# vpac_targetdb register map
Vendor: Texas Instruments
Registers are 32-bit, read-write, no defined reset value unless marked. A register's access mark holds for its fields unless they carry their own. Offsets are as the file gives them; [hi:lo] are bit positions; {n}, {i} and the like mark numbered series; 'fields as' and 'values as' point back to an identical list.

## VPAC (part 5 of 8) — Vision Pre-Processing Accelerator (VPAC)
{0x1CC+4i} GLBCE_FWD_PERCEPT_LUT_{i:02} access per field (i=0..64) — Forward Perception LUT
  [15:0] VAL rw — LUT Value
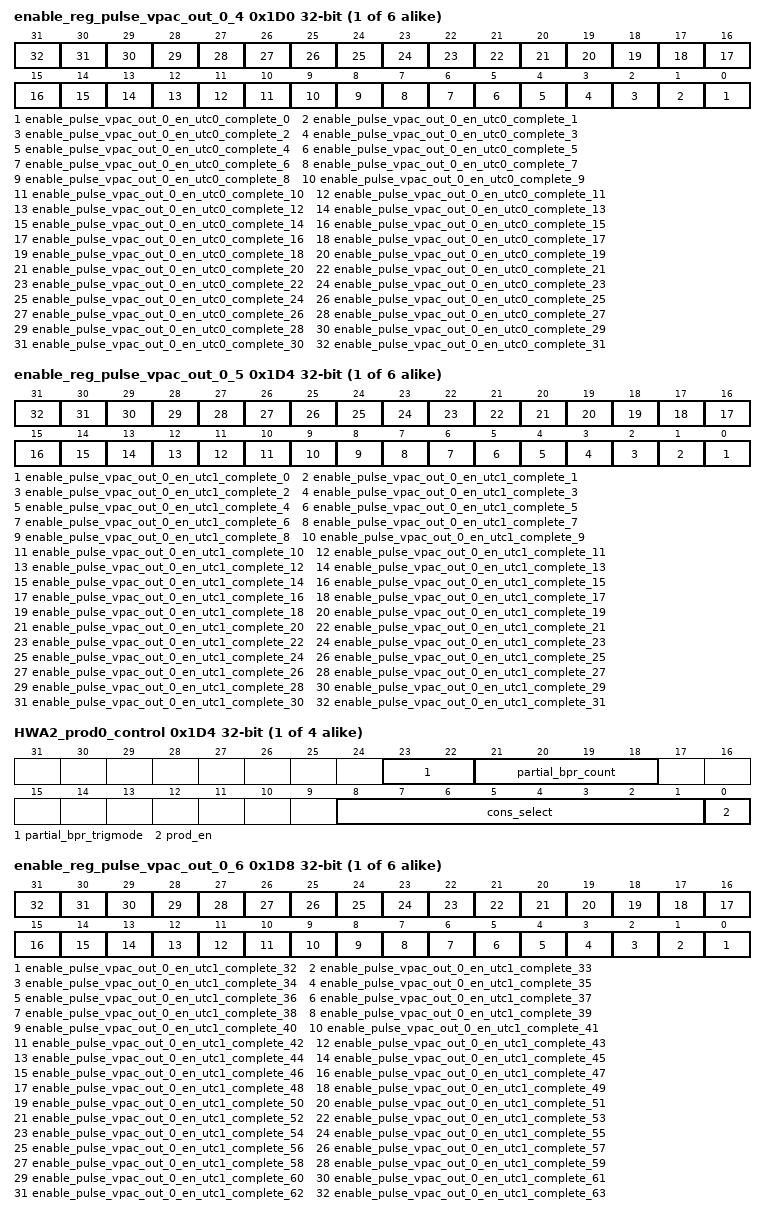
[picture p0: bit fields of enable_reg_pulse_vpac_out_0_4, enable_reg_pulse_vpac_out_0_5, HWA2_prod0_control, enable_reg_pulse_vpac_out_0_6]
{0x1D0+0x20*i} enable_reg_pulse_vpac_out_{i}_4 (i=0..5) — Enable Register {8i+52}
  [n] enable_pulse_vpac_out_{i}_en_utc0_complete_{n} (n=0..31) — Enable Set for pulse_vpac_out_{i}_en_utc0_complete_{n}
{0x1D4+0x20*i} enable_reg_pulse_vpac_out_{i}_5 (i=0..5) — Enable Register {8i+53}
  [n] enable_pulse_vpac_out_{i}_en_utc1_complete_{n} (n=0..31) — Enable Set for pulse_vpac_out_{i}_en_utc1_complete_{n}
{0x1D4+0x14*i} HWA2_prod{i}_control (i=0..3) — Controlling producer socket{i} for HWA2
  [23:22] partial_bpr_trigmode — 0: Normal behavior; 1 : Prod Socket {i} is used to trigger DMA channel to transfer end of Row or End of Region Row buffer data for prod socket ({i}+2)%4. Useful when this Buffer is not completely filled at end of row and it enables triggering separate DMA channel for end of row. Rely on tdone_bpr_early attribute; 2: Prod Socket {i} is used to trigger DMA channel to transfer end of Row or End of Region Row buffer data for prod socket ({i}+2)%4. Useful when this Buffer is not completely filled at end of row and it enables triggering separate DMA channel for end of row. Rely on end of Row attribute. Must not be used in dual output mode
  [21:18] partial_bpr_count — Remaining block count to complete configured BPR at End of Row or End of Region Row when LDC is configured in tdone_gen_mode='0'
  [8:1] cons_select — consumer select for HWA2 prod socket {i}. Used in decrementing count of producer buffer
  [0] prod_en — '1' -> Producer socket 0 enable , '0' Disable
{0x1D8+0x20*i} enable_reg_pulse_vpac_out_{i}_6 (i=0..5) — Enable Register {8i+54}
  [n-32] enable_pulse_vpac_out_{i}_en_utc1_complete_{n} (n=32..63) — Enable Set for pulse_vpac_out_{i}_en_utc1_complete_{n}
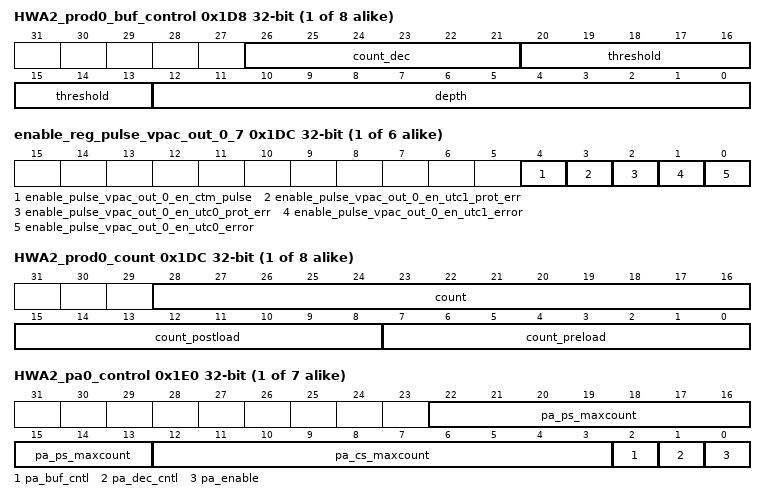
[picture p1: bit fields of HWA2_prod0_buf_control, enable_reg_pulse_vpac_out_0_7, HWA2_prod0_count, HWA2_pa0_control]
{0x1D8+0x14*i} HWA2_prod{i}_buf_control (i=0..7) — Controlling producer socket{i} buffer for HWA2
  [26:21] count_dec — Count decrement value for prod count
  [20:13] threshold — Count threshold to generate pend for consumer
  [12:0] depth — Maximum number of producer buffer count
{0x1DC+0x20*i} enable_reg_pulse_vpac_out_{i}_7 (i=0..5) — Enable Register {8i+55}
  [4] enable_pulse_vpac_out_{i}_en_ctm_pulse — Enable Set for pulse_vpac_out_{i}_en_ctm_pulse
  [3] enable_pulse_vpac_out_{i}_en_utc1_prot_err — Enable Set for pulse_vpac_out_{i}_en_utc1_prot_err
  [2] enable_pulse_vpac_out_{i}_en_utc0_prot_err — Enable Set for pulse_vpac_out_{i}_en_utc0_prot_err
  [1] enable_pulse_vpac_out_{i}_en_utc1_error — Enable Set for pulse_vpac_out_{i}_en_utc1_error
  [0] enable_pulse_vpac_out_{i}_en_utc0_error — Enable Set for pulse_vpac_out_{i}_en_utc0_error
{0x1DC+0x14*i} HWA2_prod{i}_count access per field (i=0..7) — Defining count values for pre/post load for generating pend by HWA2 prod{i}
  [28:16] count ro — current count value
  [15:8] count_postload rw — count postload after producer max thread count reached
  [7:0] count_preload rw — count preload after scheduler start/init
{0x1E0+0x14*i} HWA2_pa{i}_control (i=0..6) — control register to manage pattern adapter on HWA2 prod socket{i}
  [22:13] pa_ps_maxcount — destination count for pattern adaptation (N), M --> N
  [12:3] pa_cs_maxcount — source count for pattern adaptation (M), M --> N
  [2] pa_buf_cntl — '1' -> Apply threshold, count_preload and count_postload on pattern adapter count (use this only when pa_enable='1') '0' -> Apply threshold, count_preload and count_postload on prod count (same behavior as if no pattern adapter. Note when pa_enable='1' and pa_buf_cntl='0' threshold is not used and ignored)
  [1] pa_dec_cntl — '1' -> post pattern adaptation, decrement ps count by count_dec , '0' -> post pattern adaptation, decrement ps count by pa_cs_maxcount
  [0] pa_enable — '1' -> pa enable, '0' -> disable
0x1E0 dbg ro — The DBG register returns the current status of internal FSM - TI internal use only.
  [31:0] status — Debug status
0x1E0 dbg ro — The DBG register returns the current status of internal FSM - TI internal use only.
  [31:0] status — Debug status
0x1E0 dbg ro — The DBG register returns the current status of internal FSM - TI internal use only.
  [31:0] status — Debug status
0x1E0 dbg ro — The DBG register returns the current status of internal FSM - TI internal use only.
  [31:0] status — Debug status
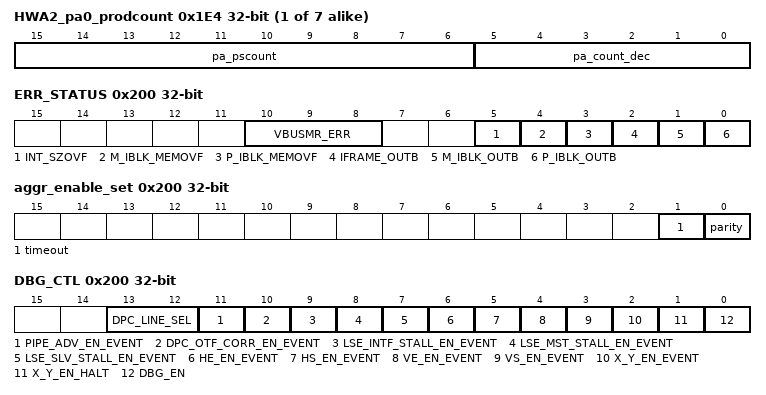
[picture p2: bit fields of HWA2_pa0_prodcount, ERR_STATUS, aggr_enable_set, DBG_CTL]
{0x1E4+0x14*i} HWA2_pa{i}_prodcount access per field (i=0..6) — count values for HWA2 prod socket{i}
  [15:6] pa_pscount ro — current count value of pa prod count
  [5:0] pa_count_dec rw — Decrement count value of pa_prod_count after pattern adapter prod count reaches threshold
0x200 aggr_enable_set — AGGR interrupt enable set Register
  [1] timeout — interrupt enable set for svbus timeout errors
  [0] parity — interrupt enable set for parity errors
0x200 aggr_enable_set — AGGR interrupt enable set Register
  fields as aggr_enable_set
0x200 ERR_STATUS — Control VBUSM Read Interface
  [10:8] VBUSMR_ERR — VBUSM Read I/F Last Error Status. Write '1' to clear, works independently for each bit.
  [5] INT_SZOVF — Internal operation has overflown the HW supported block or frame sizes. Should be fixed
  [4] M_IBLK_MEMOVF — Mesh block storage requirement is more than internal memory available. Should be fixed
  [3] P_IBLK_MEMOVF — Input pixel block storage requirement is more than internal memory available. Should be fixed
  [2] IFRAME_OUTB — Either Mesh data or Input pixel data required is going out of valid frame available
  [1] M_IBLK_OUTB — Mesh Input Block out of Bound. Mesh data required for block is not available in the prefetched internal memory. Should be fine.
  [0] P_IBLK_OUTB — Pixel Input Block out of Bound. Pixel data required for block is not available in the prefetched internal memory. PIX_PAD is not enough
0x200 aggr_enable_set — AGGR interrupt enable set Register
  fields as aggr_enable_set
0x200 DBG_CTL — debug event and control register
  [13:12] DPC_LINE_SEL — select for which dpc line ram to read on debug interface
  [11] PIPE_ADV_EN_EVENT — enable for pixal pipe line advanced
  [10] DPC_OTF_CORR_EN_EVENT — enable for dpc otf corrected a pixel
  [9] LSE_INTF_STALL_EN_EVENT — enable for lse slave port stalled by rawfe
  [8] LSE_MST_STALL_EN_EVENT — enable for lse maaster port stalled on H3A out I/F
  [7] LSE_SLV_STALL_EN_EVENT — enable for lse not sending data in frame on pixel I/F
  [6] HE_EN_EVENT — enable for horizantal end
  [5] HS_EN_EVENT — enable for horizantal start
  [4] VE_EN_EVENT — enable for verticle end
  [3] VS_EN_EVENT — enable for verticle start
  [2] X_Y_EN_EVENT — enable for x,y position match event; Only generates event, no halt
  [1] X_Y_EN_HALT — enable for x,y position match halt; Halts Pipe, clear this bit to resume. Only way to resume is to clear this bit back to 0. You would need to clear the status bit after clearing this bit.
  [0] DBG_EN — Enable debug features, set to '0' to disable all events
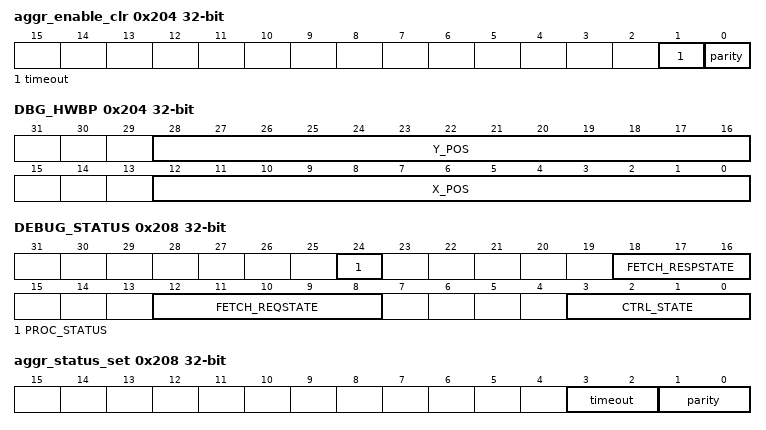
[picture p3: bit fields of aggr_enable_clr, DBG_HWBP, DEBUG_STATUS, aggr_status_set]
0x204 aggr_enable_clr — AGGR interrupt enable clear Register
  [1] timeout — interrupt enable clear for svbus timeout errors
  [0] parity — interrupt enable clear for parity errors
0x204 aggr_enable_clr — AGGR interrupt enable clear Register
  fields as aggr_enable_clr
0x204 DEBUG_CTRL — Control the memory access selection
  [0] CFG_MEMACC_SEL — VBUSP Configuration access control. 0 - VBUSP can access Ping memories 1 - VBUSP can access pong memories All private memories Mesh,Luma, Chroma will share same control. Ping and pong memories will have same memory map
0x204 aggr_enable_clr — AGGR interrupt enable clear Register
  fields as aggr_enable_clr
0x204 DBG_HWBP — x,y event for event matching
  [28:16] Y_POS — pixel y position
  [12:0] X_POS — pixel x position
0x208 aggr_status_set — AGGR interrupt status set Register
  [3:2] timeout — interrupt status set for svbus timeout errors
  [1:0] parity — interrupt status set for parity errors
0x208 aggr_status_set — AGGR interrupt status set Register
  fields as aggr_status_set
0x208 DEBUG_STATUS ro — LDC Debug Status Register
  [24] PROC_STATUS — Block Processing status. 0 - Block Processing is ongoing 1 - Either block processing is completed or not started
  [18:16] FETCH_RESPSTATE — VBUSM Fetch Response state machine 3'd0 = ST_RESP_IDLE 3'd1 = ST_RESP_MREQWAIT 3'd2 = ST_RESP_MRESPWAIT 3'd3 = ST_RESP_IREQWAIT 3'd4 = ST_RESP_IRESPWAIT 3'd5 = ST_RESP_DONE
  [12:8] FETCH_REQSTATE — VBUSM Fetch Request state machine 5'b00_000 = ST_REQ_IDLE 5'b10_000 = ST_REQ_MBASECAL 5'b10_001 = ST_REQ_MDATA 5'b11_000 = ST_REQ_INITWAIT 5'b11_001 = ST_REQ_ICBUF 5'b11_010 = ST_REQ_IBASECAL 5'b11_011 = ST_REQ_IDATA
  [3:0] CTRL_STATE — Main Control State machine 4'd0 = STATE_IDLE 4'd1 = STATE_GET_BLOCK_P1 4'd2 = STATE_GET_BLOCK_P2 4'd3 = STATE_GET_BLOCK_P3 4'd4 = STATE_GET_BLOCK_P4 4'd5 = STATE_SET_BLOCK_PWARP 4'd6 = STATE_SET_BLOCK_MESHDC 4'd7 = STATE_INIT_BLOCK 4'd8 = STATE_GET_BLOCK 4'd9 = STATE_WAIT_PROCESS_DONE 4'd10 = STATE_LAST_PROCESS 4'd11 = STATE_LAST_PROCESS_DONE
0x208 aggr_status_set — AGGR interrupt status set Register
  fields as aggr_status_set
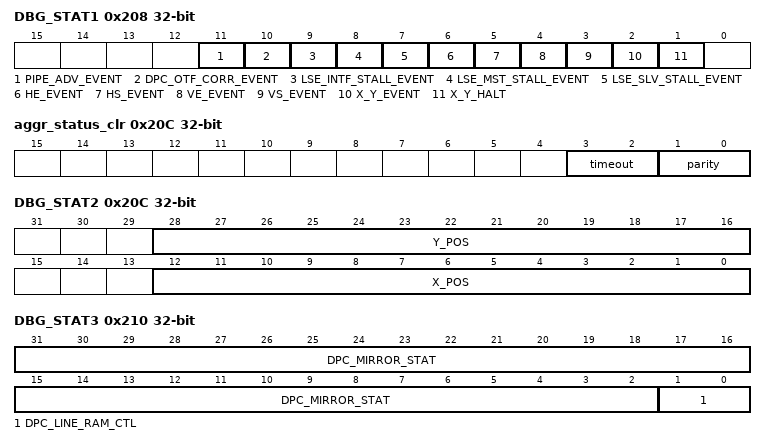
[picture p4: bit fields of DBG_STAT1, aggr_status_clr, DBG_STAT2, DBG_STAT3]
0x208 DBG_STAT1 — status/clear register for debug events
  [11] PIPE_ADV_EVENT — status/clear for pixal pipe line advanced
  [10] DPC_OTF_CORR_EVENT — status/clear for dpc otf corrected a pixel. write 1 to clear event status, write of 0 has no affect
  [9] LSE_INTF_STALL_EVENT — status/clear for lse slave port stalled by rawfe. write 1 to clear event status, write of 0 has no affect
  [8] LSE_MST_STALL_EVENT — status/clear for lse maaster port stalled. write 1 to clear event status, write of 0 has no affect
  [7] LSE_SLV_STALL_EVENT — status/clear for lse not sending data in frame. write 1 to clear event status, write of 0 has no affect
  [6] HE_EVENT — status/clear for horizantal end. write 1 to clear event status, write of 0 has no affect
  [5] HS_EVENT — status/clear for horizantal start. write 1 to clear event status, write of 0 has no affect
  [4] VE_EVENT — status/clear for verticle end. write 1 to clear event status, write of 0 has no affect
  [3] VS_EVENT — status/clear for verticle start. write 1 to clear event status, write of 0 has no affect
  [2] X_Y_EVENT — status/clear for x,y position match event. write 1 to clear event status, write of 0 has no affect
  [1] X_Y_HALT — status/clear for x,y position match halt. write 1 to clear event status, write of 0 has no affect
0x20C aggr_status_clr — AGGR interrupt status clear Register
  [3:2] timeout — interrupt status clear for svbus timeout errors
  [1:0] parity — interrupt status clear for parity errors
0x20C aggr_status_clr — AGGR interrupt status clear Register
  fields as aggr_status_clr
0x20C FR_PDFTCH ro — Pixel bytes fetched by VBUSM Read Interface. It is updated on every command issued and cleared at the beginning frame fetch. Reading at the end of the frame will provide total number of pixel data fetched for entire frame
  [31:0] PBYTES — Pixel bytes fetched for current Frame. Reading at the end of frame will provide pixel data fetched for entire frame
0x20C aggr_status_clr — AGGR interrupt status clear Register
  fields as aggr_status_clr
0x20C DBG_STAT2 ro — current x,y position in frame
  [28:16] Y_POS — current y position
  [12:0] X_POS — current x position
0x210 FR_MDFTCH ro — Mesh bytes fetched by VBUSM Read Interface. It is updated on every command issued and cleared at the beginning frame fetch. Reading at the end of the frame will provide total number of mesh data band fetched for entire frame
  [31:0] MBYTES — Mesh bytes fetched for current Frame. Reading at the end of frame will provide Mesh data fetched for entire frame
0x210 DBG_STAT3 ro — internal state status
  [31:2] DPC_MIRROR_STAT — dpc mirror status
  [1:0] DPC_LINE_RAM_CTL — ram control for understanding the phase of DPC line rams circular buffer for debug reads
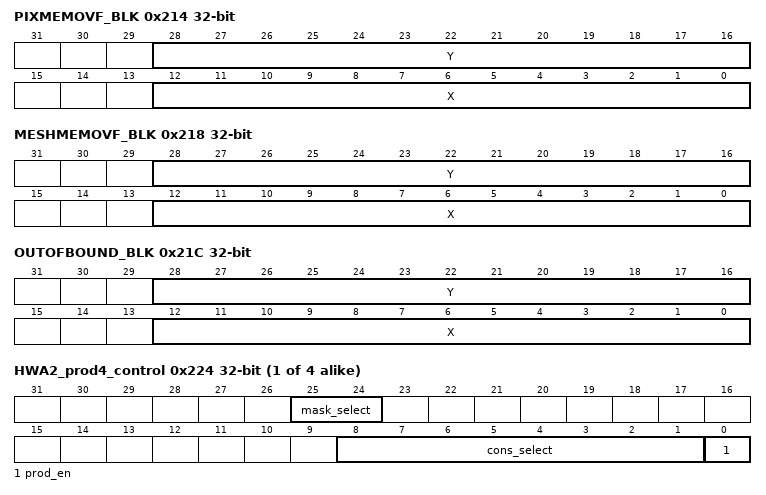
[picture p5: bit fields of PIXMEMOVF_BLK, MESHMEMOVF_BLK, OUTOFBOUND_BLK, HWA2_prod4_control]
0x214 PIXMEMOVF_BLK ro — Starting co-ordinates of first output block for which input pixel buffer overflowed
  [28:16] Y — Start Y Co-ordinate
  [12:0] X — Start X Co-ordinate
0x214 DBG_STAT4 ro — internal state status
  [31:0] LSC_DBG_STAT — lsc state machine
0x218 MESHMEMOVF_BLK ro — Starting co-ordinates of first output block for which input mesh buffer overflowed
  [28:16] Y — Start Y Co-ordinate
  [12:0] X — Start X Co-ordinate
0x21C OUTOFBOUND_BLK ro — Starting co-ordinates of first output block for which PIX_PAD is not enough
  [28:16] Y — Start Y Co-ordinate
  [12:0] X — Start X Co-ordinate
{0x1D4+0x14*i} HWA2_prod{i}_control (i=4..7) — Controlling producer socket{i} for HWA2
  [25:24] mask_select — define which tdone_mask apply to prod socket {i}. tdone_mask[mask_select] applies to prod_socket{i}.
  [8:1] cons_select — consumer select for HWA2 prod socket {i}. Used in decrementing count of producer buffer
  [0] prod_en — '1' -> Producer socket 0 enable , '0' Disable
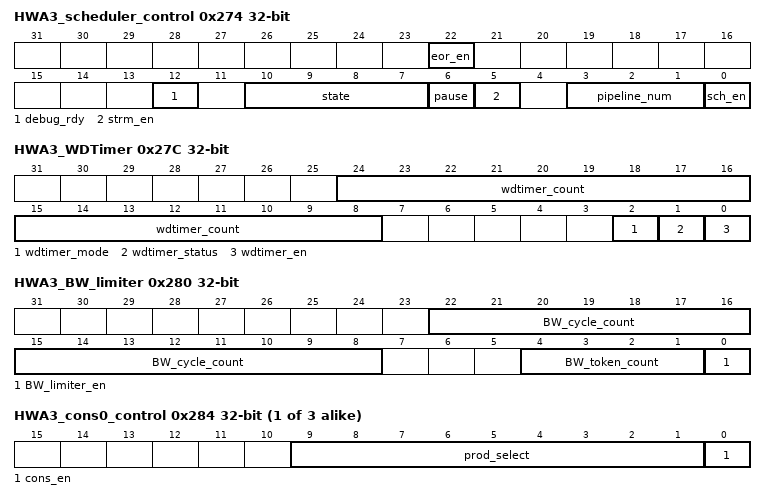
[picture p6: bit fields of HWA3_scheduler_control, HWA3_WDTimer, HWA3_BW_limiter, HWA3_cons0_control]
0x274 HWA3_scheduler_control access per field — Scheduler Control Register
  [22] eor_en rw — '1' -> LDC REGION/sub-frame feature enabled, '0' LDC works in Frame mode only
  [12] debug_rdy rw — '0' -> HWA3 Scheduler resources must not be read during halted state. '1'-> HWA3 Scheduler resources are readable during halted state
  [10:7] state ro — Current state of HWA3 Scheduler
  [6] pause rw — '1' -> pause/suspend scheduler , '0' -> resume scheduler
  [5] strm_en rw — '1' -> Streaming input enable, '0' No streaming input
  [3:1] pipeline_num rw — Pipeline Number of HWA3 Scheduler
  [0] sch_en rw — scheduler enable; write '1' to enable scheduler
0x27C HWA3_WDTimer access per field — Watchdog timer control register
  [24:8] wdtimer_count ro — Current value of HWA3 Scheduler watchdog timer count
  [2] wdtimer_mode rw — Watchdog timeout count '1' -> 128K , '0' -> 64K
  [1] wdtimer_status ro — HWA3 Scheduler watchdog timer status '1' -> Timer Active '0' -> Timer Inactive (count is stable)
  [0] wdtimer_en rw — '1' -> activate watchdog timer for 64K VPAC/DMPAC cycles between task start and task done '0' -> Disable watchdog timer
0x280 HWA3_BW_limiter — Scheduler BW Control Register. Processing unit level BW control. Use DMA to eliminate peak system BW within processing units line/Block
  [22:8] BW_cycle_count — Average Cycle count between successive Task Start
  [4:1] BW_token_count — Max Token count to create average BW
  [0] BW_limiter_en — '1' -> Enable BW limiter function for HWA3 sch, '0' --> Disable
{0x284+4i} HWA3_cons{i}_control (i=0..2) — Controlling consumer socket {i} for HWA3
  [9:1] prod_select — producer select for HWA3 cons socket {i}
  [0] cons_en — '1' -> Consumer socket {i} enable , '0' Disable
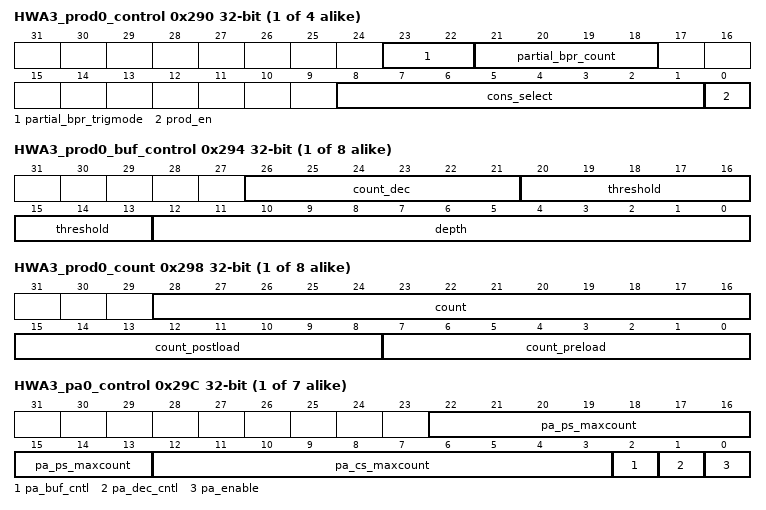
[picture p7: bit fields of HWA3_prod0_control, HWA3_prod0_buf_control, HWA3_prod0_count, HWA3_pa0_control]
{0x290+0x14*i} HWA3_prod{i}_control (i=0..3) — Controlling producer socket{i} for HWA3
  [23:22] partial_bpr_trigmode — 0: Normal behavior; 1 : Prod Socket {i} is used to trigger DMA channel to transfer end of Row or End of Region Row buffer data for prod socket ({i}+2)%4. Useful when this Buffer is not completely filled at end of row and it enables triggering separate DMA channel for end of row. Rely on tdone_bpr_early attribute; 2: Prod Socket {i} is used to trigger DMA channel to transfer end of Row or End of Region Row buffer data for prod socket ({i}+2)%4. Useful when this Buffer is not completely filled at end of row and it enables triggering separate DMA channel for end of row. Rely on end of Row attribute. Must not be used in dual output mode
  [21:18] partial_bpr_count — Remaining block count to complete configured BPR at End of Row or End of Region Row when LDC is configured in tdone_gen_mode='0'
  [8:1] cons_select — consumer select for HWA3 prod socket {i}. Used in decrementing count of producer buffer
  [0] prod_en — '1' -> Producer socket 0 enable , '0' Disable
{0x294+0x14*i} HWA3_prod{i}_buf_control (i=0..7) — Controlling producer socket{i} buffer for HWA3
  fields as HWA2_prod0_buf_control
{0x298+0x14*i} HWA3_prod{i}_count access per field (i=0..7) — Defining count values for pre/post load for generating pend by HWA3 prod{i}
  fields as HWA2_prod0_count
{0x29C+0x14*i} HWA3_pa{i}_control (i=0..6) — control register to manage pattern adapter on HWA3 prod socket{i}
  fields as HWA2_pa0_control
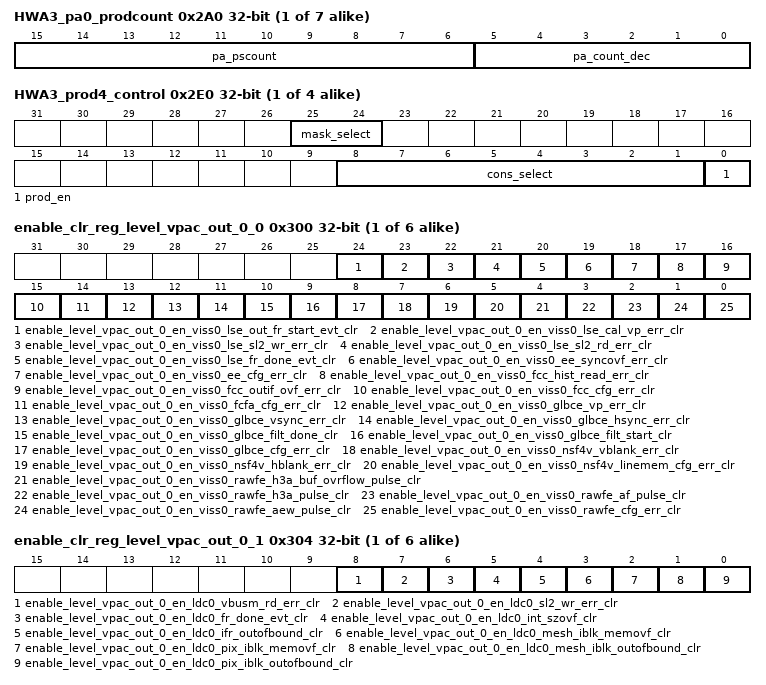
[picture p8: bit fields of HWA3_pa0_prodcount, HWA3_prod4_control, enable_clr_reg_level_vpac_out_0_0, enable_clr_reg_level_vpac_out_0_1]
{0x2A0+0x14*i} HWA3_pa{i}_prodcount access per field (i=0..6) — count values for HWA3 prod socket{i}
  fields as HWA2_pa0_prodcount
0x2D0 GLBCE_WDR_GAMMA_EN access per field — WDR Gamma LUT Enable
  [0] EN rw — Frontend WDR LUT enable
{0x2D4+4i} GLBCE_WDR_GAMMA_LUT_{i:02} access per field (i=0..99) — Frontend WDR LUT
  [15:0] VAL rw — LUT Value
{0x290+0x14*i} HWA3_prod{i}_control (i=4..7) — Controlling producer socket{i} for HWA3
  [25:24] mask_select — define which tdone_mask apply to prod socket {i}. tdone_mask[mask_select] applies to prod_socket{i}.
  [8:1] cons_select — consumer select for HWA3 prod socket {i}. Used in decrementing count of producer buffer
  [0] prod_en — '1' -> Producer socket 0 enable , '0' Disable
{0x300+0x20*i} enable_clr_reg_level_vpac_out_{i}_0 (i=0..5) — Enable Clear Register {8i}
  [24] enable_level_vpac_out_{i}_en_viss0_lse_out_fr_start_evt_clr — Enable Clear for level_vpac_out_{i}_en_viss0_lse_out_fr_start_evt
  [23] enable_level_vpac_out_{i}_en_viss0_lse_cal_vp_err_clr — Enable Clear for level_vpac_out_{i}_en_viss0_lse_cal_vp_err
  [22] enable_level_vpac_out_{i}_en_viss0_lse_sl2_wr_err_clr — Enable Clear for level_vpac_out_{i}_en_viss0_lse_sl2_wr_err
  [21] enable_level_vpac_out_{i}_en_viss0_lse_sl2_rd_err_clr — Enable Clear for level_vpac_out_{i}_en_viss0_lse_sl2_rd_err
  [20] enable_level_vpac_out_{i}_en_viss0_lse_fr_done_evt_clr — Enable Clear for level_vpac_out_{i}_en_viss0_lse_fr_done_evt
  [19] enable_level_vpac_out_{i}_en_viss0_ee_syncovf_err_clr — Enable Clear for level_vpac_out_{i}_en_viss0_ee_syncovf_err
  [18] enable_level_vpac_out_{i}_en_viss0_ee_cfg_err_clr — Enable Clear for level_vpac_out_{i}_en_viss0_ee_cfg_err
  [17] enable_level_vpac_out_{i}_en_viss0_fcc_hist_read_err_clr — Enable Clear for level_vpac_out_{i}_en_viss0_fcc_hist_read_err
  [16] enable_level_vpac_out_{i}_en_viss0_fcc_outif_ovf_err_clr — Enable Clear for level_vpac_out_{i}_en_viss0_fcc_outif_ovf_err
  [15] enable_level_vpac_out_{i}_en_viss0_fcc_cfg_err_clr — Enable Clear for level_vpac_out_{i}_en_viss0_fcc_cfg_err
  [14] enable_level_vpac_out_{i}_en_viss0_fcfa_cfg_err_clr — Enable Clear for level_vpac_out_{i}_en_viss0_fcfa_cfg_err
  [13] enable_level_vpac_out_{i}_en_viss0_glbce_vp_err_clr — Enable Clear for level_vpac_out_{i}_en_viss0_glbce_vp_err
  [12] enable_level_vpac_out_{i}_en_viss0_glbce_vsync_err_clr — Enable Clear for level_vpac_out_{i}_en_viss0_glbce_vsync_err
  [11] enable_level_vpac_out_{i}_en_viss0_glbce_hsync_err_clr — Enable Clear for level_vpac_out_{i}_en_viss0_glbce_hsync_err
  [10] enable_level_vpac_out_{i}_en_viss0_glbce_filt_done_clr — Enable Clear for level_vpac_out_{i}_en_viss0_glbce_filt_done
  [9] enable_level_vpac_out_{i}_en_viss0_glbce_filt_start_clr — Enable Clear for level_vpac_out_{i}_en_viss0_glbce_filt_start
  [8] enable_level_vpac_out_{i}_en_viss0_glbce_cfg_err_clr — Enable Clear for level_vpac_out_{i}_en_viss0_glbce_cfg_err
  [7] enable_level_vpac_out_{i}_en_viss0_nsf4v_vblank_err_clr — Enable Clear for level_vpac_out_{i}_en_viss0_nsf4v_vblank_err
  [6] enable_level_vpac_out_{i}_en_viss0_nsf4v_hblank_err_clr — Enable Clear for level_vpac_out_{i}_en_viss0_nsf4v_hblank_err
  [5] enable_level_vpac_out_{i}_en_viss0_nsf4v_linemem_cfg_err_clr — Enable Clear for level_vpac_out_{i}_en_viss0_nsf4v_linemem_cfg_err
  [4] enable_level_vpac_out_{i}_en_viss0_rawfe_h3a_buf_ovrflow_pulse_clr — Enable Clear for level_vpac_out_{i}_en_viss0_rawfe_h3a_buf_ovrflow_pulse
  [3] enable_level_vpac_out_{i}_en_viss0_rawfe_h3a_pulse_clr — Enable Clear for level_vpac_out_{i}_en_viss0_rawfe_h3a_pulse
  [2] enable_level_vpac_out_{i}_en_viss0_rawfe_af_pulse_clr — Enable Clear for level_vpac_out_{i}_en_viss0_rawfe_af_pulse
  [1] enable_level_vpac_out_{i}_en_viss0_rawfe_aew_pulse_clr — Enable Clear for level_vpac_out_{i}_en_viss0_rawfe_aew_pulse
  [0] enable_level_vpac_out_{i}_en_viss0_rawfe_cfg_err_clr — Enable Clear for level_vpac_out_{i}_en_viss0_rawfe_cfg_err
{0x304+0x20*i} enable_clr_reg_level_vpac_out_{i}_1 (i=0..5) — Enable Clear Register {8i+1}
  [8] enable_level_vpac_out_{i}_en_ldc0_vbusm_rd_err_clr — Enable Clear for level_vpac_out_{i}_en_ldc0_vbusm_rd_err
  [7] enable_level_vpac_out_{i}_en_ldc0_sl2_wr_err_clr — Enable Clear for level_vpac_out_{i}_en_ldc0_sl2_wr_err
  [6] enable_level_vpac_out_{i}_en_ldc0_fr_done_evt_clr — Enable Clear for level_vpac_out_{i}_en_ldc0_fr_done_evt
  [5] enable_level_vpac_out_{i}_en_ldc0_int_szovf_clr — Enable Clear for level_vpac_out_{i}_en_ldc0_int_szovf
  [4] enable_level_vpac_out_{i}_en_ldc0_ifr_outofbound_clr — Enable Clear for level_vpac_out_{i}_en_ldc0_ifr_outofbound
  [3] enable_level_vpac_out_{i}_en_ldc0_mesh_iblk_memovf_clr — Enable Clear for level_vpac_out_{i}_en_ldc0_mesh_iblk_memovf
  [2] enable_level_vpac_out_{i}_en_ldc0_pix_iblk_memovf_clr — Enable Clear for level_vpac_out_{i}_en_ldc0_pix_iblk_memovf
  [1] enable_level_vpac_out_{i}_en_ldc0_mesh_iblk_outofbound_clr — Enable Clear for level_vpac_out_{i}_en_ldc0_mesh_iblk_outofbound
  [0] enable_level_vpac_out_{i}_en_ldc0_pix_iblk_outofbound_clr — Enable Clear for level_vpac_out_{i}_en_ldc0_pix_iblk_outofbound
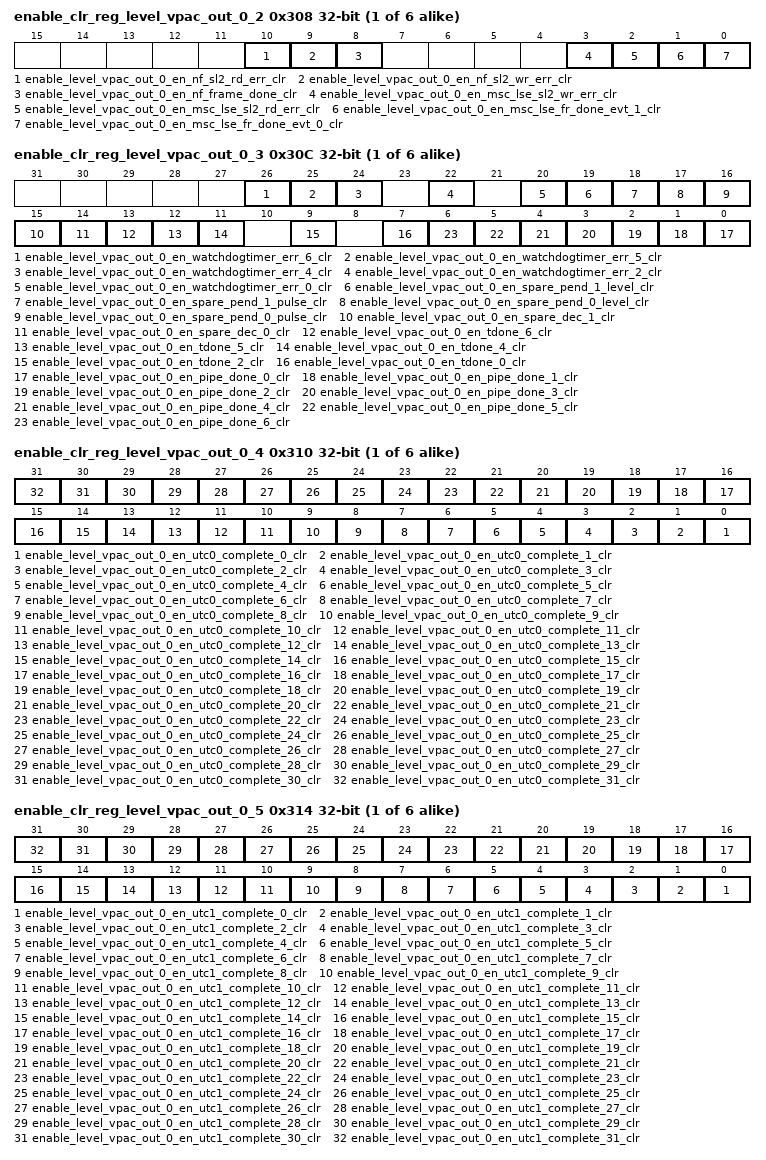
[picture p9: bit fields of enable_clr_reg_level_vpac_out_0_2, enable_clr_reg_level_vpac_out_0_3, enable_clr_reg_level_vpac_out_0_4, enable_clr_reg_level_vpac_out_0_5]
{0x308+0x20*i} enable_clr_reg_level_vpac_out_{i}_2 (i=0..5) — Enable Clear Register {8i+2}
  [10] enable_level_vpac_out_{i}_en_nf_sl2_rd_err_clr — Enable Clear for level_vpac_out_{i}_en_nf_sl2_rd_err
  [9] enable_level_vpac_out_{i}_en_nf_sl2_wr_err_clr — Enable Clear for level_vpac_out_{i}_en_nf_sl2_wr_err
  [8] enable_level_vpac_out_{i}_en_nf_frame_done_clr — Enable Clear for level_vpac_out_{i}_en_nf_frame_done
  [3] enable_level_vpac_out_{i}_en_msc_lse_sl2_wr_err_clr — Enable Clear for level_vpac_out_{i}_en_msc_lse_sl2_wr_err
  [2] enable_level_vpac_out_{i}_en_msc_lse_sl2_rd_err_clr — Enable Clear for level_vpac_out_{i}_en_msc_lse_sl2_rd_err
  [1] enable_level_vpac_out_{i}_en_msc_lse_fr_done_evt_1_clr — Enable Clear for level_vpac_out_{i}_en_msc_lse_fr_done_evt_1
  [0] enable_level_vpac_out_{i}_en_msc_lse_fr_done_evt_0_clr — Enable Clear for level_vpac_out_{i}_en_msc_lse_fr_done_evt_0
{0x30C+0x20*i} enable_clr_reg_level_vpac_out_{i}_3 (i=0..5) — Enable Clear Register {8i+3}
  [26] enable_level_vpac_out_{i}_en_watchdogtimer_err_6_clr — Enable Clear for level_vpac_out_{i}_en_watchdogtimer_err_6
  [25] enable_level_vpac_out_{i}_en_watchdogtimer_err_5_clr — Enable Clear for level_vpac_out_{i}_en_watchdogtimer_err_5
  [24] enable_level_vpac_out_{i}_en_watchdogtimer_err_4_clr — Enable Clear for level_vpac_out_{i}_en_watchdogtimer_err_4
  [22] enable_level_vpac_out_{i}_en_watchdogtimer_err_2_clr — Enable Clear for level_vpac_out_{i}_en_watchdogtimer_err_2
  [20] enable_level_vpac_out_{i}_en_watchdogtimer_err_0_clr — Enable Clear for level_vpac_out_{i}_en_watchdogtimer_err_0
  [19] enable_level_vpac_out_{i}_en_spare_pend_1_level_clr — Enable Clear for level_vpac_out_{i}_en_spare_pend_1_level
  [18] enable_level_vpac_out_{i}_en_spare_pend_1_pulse_clr — Enable Clear for level_vpac_out_{i}_en_spare_pend_1_pulse
  [17] enable_level_vpac_out_{i}_en_spare_pend_0_level_clr — Enable Clear for level_vpac_out_{i}_en_spare_pend_0_level
  [16] enable_level_vpac_out_{i}_en_spare_pend_0_pulse_clr — Enable Clear for level_vpac_out_{i}_en_spare_pend_0_pulse
  [15] enable_level_vpac_out_{i}_en_spare_dec_1_clr — Enable Clear for level_vpac_out_{i}_en_spare_dec_1
  [14] enable_level_vpac_out_{i}_en_spare_dec_0_clr — Enable Clear for level_vpac_out_{i}_en_spare_dec_0
  [13] enable_level_vpac_out_{i}_en_tdone_6_clr — Enable Clear for level_vpac_out_{i}_en_tdone_6
  [12] enable_level_vpac_out_{i}_en_tdone_5_clr — Enable Clear for level_vpac_out_{i}_en_tdone_5
  [11] enable_level_vpac_out_{i}_en_tdone_4_clr — Enable Clear for level_vpac_out_{i}_en_tdone_4
  [9] enable_level_vpac_out_{i}_en_tdone_2_clr — Enable Clear for level_vpac_out_{i}_en_tdone_2
  [7] enable_level_vpac_out_{i}_en_tdone_0_clr — Enable Clear for level_vpac_out_{i}_en_tdone_0
  [n] enable_level_vpac_out_{i}_en_pipe_done_{n}_clr (n=0..6) — Enable Clear for level_vpac_out_{i}_en_pipe_done_{n}
{0x310+0x20*i} enable_clr_reg_level_vpac_out_{i}_4 (i=0..5) — Enable Clear Register {8i+4}
  [n] enable_level_vpac_out_{i}_en_utc0_complete_{n}_clr (n=0..31) — Enable Clear for level_vpac_out_{i}_en_utc0_complete_{n}
{0x314+0x20*i} enable_clr_reg_level_vpac_out_{i}_5 (i=0..5) — Enable Clear Register {8i+5}
  [n] enable_level_vpac_out_{i}_en_utc1_complete_{n}_clr (n=0..31) — Enable Clear for level_vpac_out_{i}_en_utc1_complete_{n}
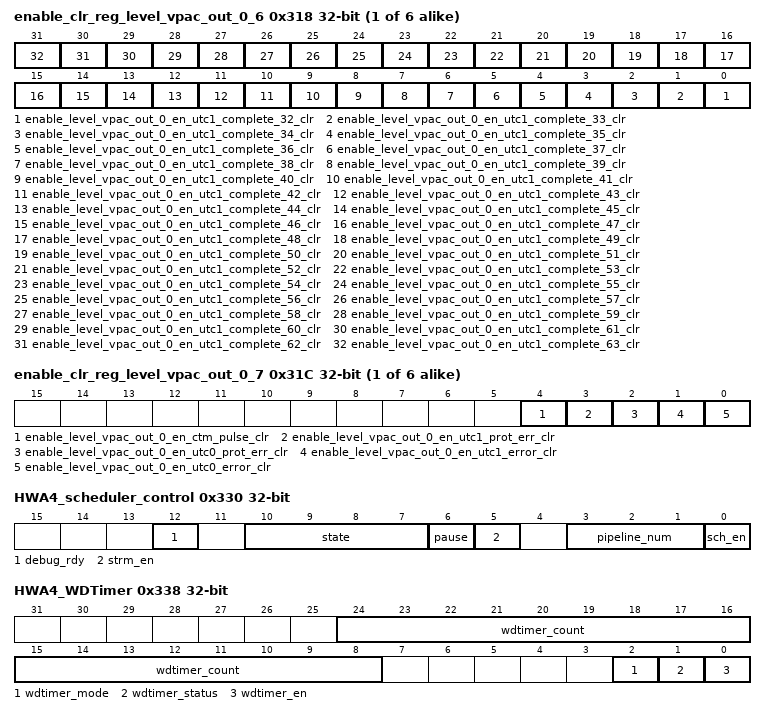
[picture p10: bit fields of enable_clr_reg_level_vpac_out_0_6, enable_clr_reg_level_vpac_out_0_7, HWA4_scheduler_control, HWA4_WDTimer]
{0x318+0x20*i} enable_clr_reg_level_vpac_out_{i}_6 (i=0..5) — Enable Clear Register {8i+6}
  [n-32] enable_level_vpac_out_{i}_en_utc1_complete_{n}_clr (n=32..63) — Enable Clear for level_vpac_out_{i}_en_utc1_complete_{n}
{0x31C+0x20*i} enable_clr_reg_level_vpac_out_{i}_7 (i=0..5) — Enable Clear Register {8i+7}
  [4] enable_level_vpac_out_{i}_en_ctm_pulse_clr — Enable Clear for level_vpac_out_{i}_en_ctm_pulse
  [3] enable_level_vpac_out_{i}_en_utc1_prot_err_clr — Enable Clear for level_vpac_out_{i}_en_utc1_prot_err
  [2] enable_level_vpac_out_{i}_en_utc0_prot_err_clr — Enable Clear for level_vpac_out_{i}_en_utc0_prot_err
  [1] enable_level_vpac_out_{i}_en_utc1_error_clr — Enable Clear for level_vpac_out_{i}_en_utc1_error
  [0] enable_level_vpac_out_{i}_en_utc0_error_clr — Enable Clear for level_vpac_out_{i}_en_utc0_error
0x330 HWA4_scheduler_control access per field — Scheduler Control Register
  [12] debug_rdy rw — '0' -> HWA4 Scheduler resources must not be read during halted state. '1'-> HWA4 Scheduler resources are readable during halted state
  [10:7] state ro — Current state of HWA4 Scheduler
  [6] pause rw — '1' -> pause/suspend scheduler , '0' -> resume scheduler
  [5] strm_en rw — '1' -> Streaming input enable, '0' No streaming input
  [3:1] pipeline_num rw — Pipeline Number of HWA4 Scheduler
  [0] sch_en rw — scheduler enable; write '1' to enable scheduler
0x338 HWA4_WDTimer access per field — Watchdog timer control register
  [24:8] wdtimer_count ro — Current value of HWA4 Scheduler watchdog timer count
  [2] wdtimer_mode rw — Watchdog timeout count '1' -> 128K , '0' -> 64K
  [1] wdtimer_status ro — HWA4 Scheduler watchdog timer status '1' -> Timer Active '0' -> Timer Inactive (count is stable)
  [0] wdtimer_en rw — '1' -> activate watchdog timer for 64K VPAC/DMPAC cycles between task start and task done '0' -> Disable watchdog timer
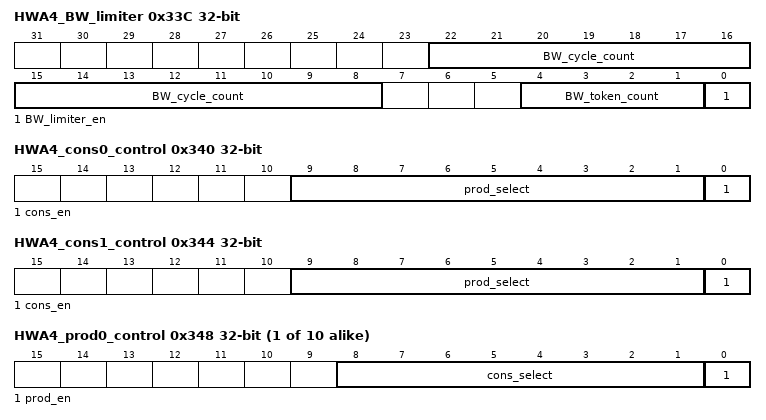
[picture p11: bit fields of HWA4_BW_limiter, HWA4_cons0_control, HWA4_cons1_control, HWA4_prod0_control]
0x33C HWA4_BW_limiter — Scheduler BW Control Register. Processing unit level BW control. Use DMA to eliminate peak system BW within processing units line/Block
  [22:8] BW_cycle_count — Average Cycle count between successive Task Start
  [4:1] BW_token_count — Max Token count to create average BW
  [0] BW_limiter_en — '1' -> Enable BW limiter function for HWA4 sch, '0' --> Disable
0x340 HWA4_cons0_control — Controlling consumer socket 0 for HWA4
  [9:1] prod_select — producer select for HWA4 cons socket 0
  [0] cons_en — '1' -> Consumer socket 0 enable , '0' Disable
0x344 HWA4_cons1_control — Controlling consumer socket 1 for HWA4
  [9:1] prod_select — producer select for HWA4 cons socket 1
  [0] cons_en — '1' -> Consumer socket 1 enable , '0' Disable
{0x348+0x14*i} HWA4_prod{i}_control (i=0..9) — Controlling producer socket{i} for HWA4
  [8:1] cons_select — consumer select for HWA4 prod socket {i}. Used in decrementing count of producer buffer
  [0] prod_en — '1' -> Producer socket 0 enable , '0' Disable
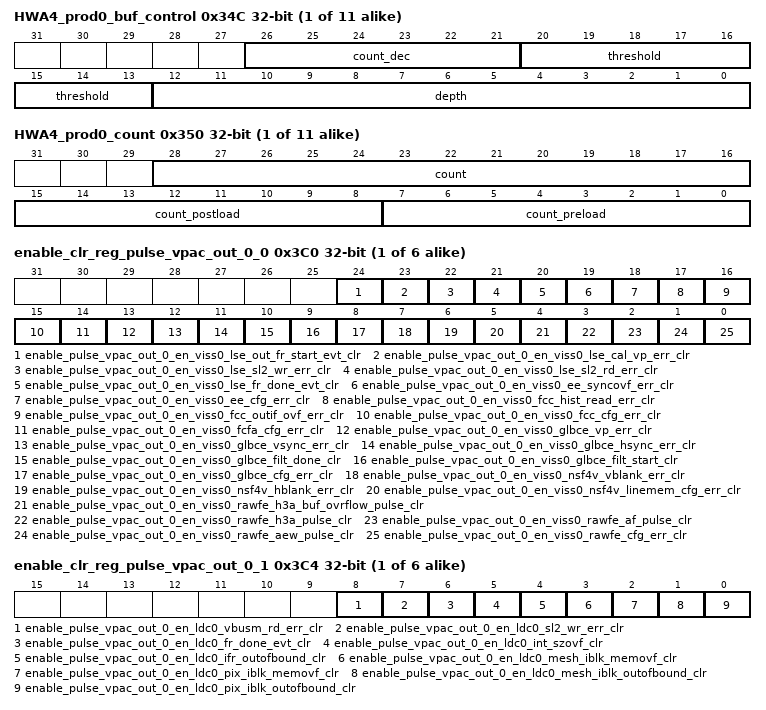
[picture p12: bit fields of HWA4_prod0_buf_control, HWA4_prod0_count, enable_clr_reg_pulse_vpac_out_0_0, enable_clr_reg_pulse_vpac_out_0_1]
{0x34C+0x14*i} HWA4_prod{i}_buf_control (i=0..10) — Controlling producer socket{i} buffer for HWA4
  fields as HWA2_prod0_buf_control
{0x350+0x14*i} HWA4_prod{i}_count access per field (i=0..10) — Defining count values for pre/post load for generating pend by HWA4 prod{i}
  fields as HWA2_prod0_count
{0x3C0+0x20*i} enable_clr_reg_pulse_vpac_out_{i}_0 (i=0..5) — Enable Clear Register {8i+48}
  [24] enable_pulse_vpac_out_{i}_en_viss0_lse_out_fr_start_evt_clr — Enable Clear for pulse_vpac_out_{i}_en_viss0_lse_out_fr_start_evt
  [23] enable_pulse_vpac_out_{i}_en_viss0_lse_cal_vp_err_clr — Enable Clear for pulse_vpac_out_{i}_en_viss0_lse_cal_vp_err
  [22] enable_pulse_vpac_out_{i}_en_viss0_lse_sl2_wr_err_clr — Enable Clear for pulse_vpac_out_{i}_en_viss0_lse_sl2_wr_err
  [21] enable_pulse_vpac_out_{i}_en_viss0_lse_sl2_rd_err_clr — Enable Clear for pulse_vpac_out_{i}_en_viss0_lse_sl2_rd_err
  [20] enable_pulse_vpac_out_{i}_en_viss0_lse_fr_done_evt_clr — Enable Clear for pulse_vpac_out_{i}_en_viss0_lse_fr_done_evt
  [19] enable_pulse_vpac_out_{i}_en_viss0_ee_syncovf_err_clr — Enable Clear for pulse_vpac_out_{i}_en_viss0_ee_syncovf_err
  [18] enable_pulse_vpac_out_{i}_en_viss0_ee_cfg_err_clr — Enable Clear for pulse_vpac_out_{i}_en_viss0_ee_cfg_err
  [17] enable_pulse_vpac_out_{i}_en_viss0_fcc_hist_read_err_clr — Enable Clear for pulse_vpac_out_{i}_en_viss0_fcc_hist_read_err
  [16] enable_pulse_vpac_out_{i}_en_viss0_fcc_outif_ovf_err_clr — Enable Clear for pulse_vpac_out_{i}_en_viss0_fcc_outif_ovf_err
  [15] enable_pulse_vpac_out_{i}_en_viss0_fcc_cfg_err_clr — Enable Clear for pulse_vpac_out_{i}_en_viss0_fcc_cfg_err
  [14] enable_pulse_vpac_out_{i}_en_viss0_fcfa_cfg_err_clr — Enable Clear for pulse_vpac_out_{i}_en_viss0_fcfa_cfg_err
  [13] enable_pulse_vpac_out_{i}_en_viss0_glbce_vp_err_clr — Enable Clear for pulse_vpac_out_{i}_en_viss0_glbce_vp_err
  [12] enable_pulse_vpac_out_{i}_en_viss0_glbce_vsync_err_clr — Enable Clear for pulse_vpac_out_{i}_en_viss0_glbce_vsync_err
  [11] enable_pulse_vpac_out_{i}_en_viss0_glbce_hsync_err_clr — Enable Clear for pulse_vpac_out_{i}_en_viss0_glbce_hsync_err
  [10] enable_pulse_vpac_out_{i}_en_viss0_glbce_filt_done_clr — Enable Clear for pulse_vpac_out_{i}_en_viss0_glbce_filt_done
  [9] enable_pulse_vpac_out_{i}_en_viss0_glbce_filt_start_clr — Enable Clear for pulse_vpac_out_{i}_en_viss0_glbce_filt_start
  [8] enable_pulse_vpac_out_{i}_en_viss0_glbce_cfg_err_clr — Enable Clear for pulse_vpac_out_{i}_en_viss0_glbce_cfg_err
  [7] enable_pulse_vpac_out_{i}_en_viss0_nsf4v_vblank_err_clr — Enable Clear for pulse_vpac_out_{i}_en_viss0_nsf4v_vblank_err
  [6] enable_pulse_vpac_out_{i}_en_viss0_nsf4v_hblank_err_clr — Enable Clear for pulse_vpac_out_{i}_en_viss0_nsf4v_hblank_err
  [5] enable_pulse_vpac_out_{i}_en_viss0_nsf4v_linemem_cfg_err_clr — Enable Clear for pulse_vpac_out_{i}_en_viss0_nsf4v_linemem_cfg_err
  [4] enable_pulse_vpac_out_{i}_en_viss0_rawfe_h3a_buf_ovrflow_pulse_clr — Enable Clear for pulse_vpac_out_{i}_en_viss0_rawfe_h3a_buf_ovrflow_pulse
  [3] enable_pulse_vpac_out_{i}_en_viss0_rawfe_h3a_pulse_clr — Enable Clear for pulse_vpac_out_{i}_en_viss0_rawfe_h3a_pulse
  [2] enable_pulse_vpac_out_{i}_en_viss0_rawfe_af_pulse_clr — Enable Clear for pulse_vpac_out_{i}_en_viss0_rawfe_af_pulse
  [1] enable_pulse_vpac_out_{i}_en_viss0_rawfe_aew_pulse_clr — Enable Clear for pulse_vpac_out_{i}_en_viss0_rawfe_aew_pulse
  [0] enable_pulse_vpac_out_{i}_en_viss0_rawfe_cfg_err_clr — Enable Clear for pulse_vpac_out_{i}_en_viss0_rawfe_cfg_err
{0x3C4+0x20*i} enable_clr_reg_pulse_vpac_out_{i}_1 (i=0..5) — Enable Clear Register {8i+49}
  [8] enable_pulse_vpac_out_{i}_en_ldc0_vbusm_rd_err_clr — Enable Clear for pulse_vpac_out_{i}_en_ldc0_vbusm_rd_err
  [7] enable_pulse_vpac_out_{i}_en_ldc0_sl2_wr_err_clr — Enable Clear for pulse_vpac_out_{i}_en_ldc0_sl2_wr_err
  [6] enable_pulse_vpac_out_{i}_en_ldc0_fr_done_evt_clr — Enable Clear for pulse_vpac_out_{i}_en_ldc0_fr_done_evt
  [5] enable_pulse_vpac_out_{i}_en_ldc0_int_szovf_clr — Enable Clear for pulse_vpac_out_{i}_en_ldc0_int_szovf
  [4] enable_pulse_vpac_out_{i}_en_ldc0_ifr_outofbound_clr — Enable Clear for pulse_vpac_out_{i}_en_ldc0_ifr_outofbound
  [3] enable_pulse_vpac_out_{i}_en_ldc0_mesh_iblk_memovf_clr — Enable Clear for pulse_vpac_out_{i}_en_ldc0_mesh_iblk_memovf
  [2] enable_pulse_vpac_out_{i}_en_ldc0_pix_iblk_memovf_clr — Enable Clear for pulse_vpac_out_{i}_en_ldc0_pix_iblk_memovf
  [1] enable_pulse_vpac_out_{i}_en_ldc0_mesh_iblk_outofbound_clr — Enable Clear for pulse_vpac_out_{i}_en_ldc0_mesh_iblk_outofbound
  [0] enable_pulse_vpac_out_{i}_en_ldc0_pix_iblk_outofbound_clr — Enable Clear for pulse_vpac_out_{i}_en_ldc0_pix_iblk_outofbound
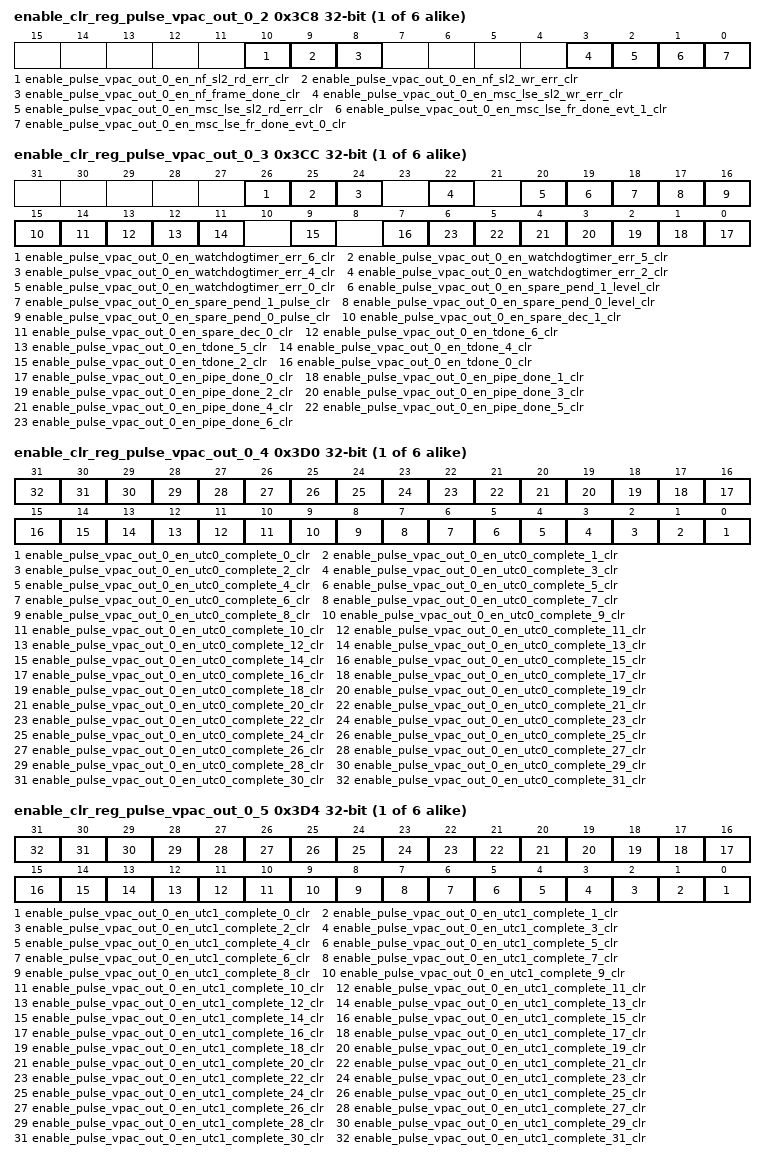
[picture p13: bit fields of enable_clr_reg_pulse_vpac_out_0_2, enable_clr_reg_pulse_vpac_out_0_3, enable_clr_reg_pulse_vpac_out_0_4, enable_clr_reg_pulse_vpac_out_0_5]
{0x3C8+0x20*i} enable_clr_reg_pulse_vpac_out_{i}_2 (i=0..5) — Enable Clear Register {8i+50}
  [10] enable_pulse_vpac_out_{i}_en_nf_sl2_rd_err_clr — Enable Clear for pulse_vpac_out_{i}_en_nf_sl2_rd_err
  [9] enable_pulse_vpac_out_{i}_en_nf_sl2_wr_err_clr — Enable Clear for pulse_vpac_out_{i}_en_nf_sl2_wr_err
  [8] enable_pulse_vpac_out_{i}_en_nf_frame_done_clr — Enable Clear for pulse_vpac_out_{i}_en_nf_frame_done
  [3] enable_pulse_vpac_out_{i}_en_msc_lse_sl2_wr_err_clr — Enable Clear for pulse_vpac_out_{i}_en_msc_lse_sl2_wr_err
  [2] enable_pulse_vpac_out_{i}_en_msc_lse_sl2_rd_err_clr — Enable Clear for pulse_vpac_out_{i}_en_msc_lse_sl2_rd_err
  [1] enable_pulse_vpac_out_{i}_en_msc_lse_fr_done_evt_1_clr — Enable Clear for pulse_vpac_out_{i}_en_msc_lse_fr_done_evt_1
  [0] enable_pulse_vpac_out_{i}_en_msc_lse_fr_done_evt_0_clr — Enable Clear for pulse_vpac_out_{i}_en_msc_lse_fr_done_evt_0
{0x3CC+0x20*i} enable_clr_reg_pulse_vpac_out_{i}_3 (i=0..5) — Enable Clear Register {8i+51}
  [26] enable_pulse_vpac_out_{i}_en_watchdogtimer_err_6_clr — Enable Clear for pulse_vpac_out_{i}_en_watchdogtimer_err_6
  [25] enable_pulse_vpac_out_{i}_en_watchdogtimer_err_5_clr — Enable Clear for pulse_vpac_out_{i}_en_watchdogtimer_err_5
  [24] enable_pulse_vpac_out_{i}_en_watchdogtimer_err_4_clr — Enable Clear for pulse_vpac_out_{i}_en_watchdogtimer_err_4
  [22] enable_pulse_vpac_out_{i}_en_watchdogtimer_err_2_clr — Enable Clear for pulse_vpac_out_{i}_en_watchdogtimer_err_2
  [20] enable_pulse_vpac_out_{i}_en_watchdogtimer_err_0_clr — Enable Clear for pulse_vpac_out_{i}_en_watchdogtimer_err_0
  [19] enable_pulse_vpac_out_{i}_en_spare_pend_1_level_clr — Enable Clear for pulse_vpac_out_{i}_en_spare_pend_1_level
  [18] enable_pulse_vpac_out_{i}_en_spare_pend_1_pulse_clr — Enable Clear for pulse_vpac_out_{i}_en_spare_pend_1_pulse
  [17] enable_pulse_vpac_out_{i}_en_spare_pend_0_level_clr — Enable Clear for pulse_vpac_out_{i}_en_spare_pend_0_level
  [16] enable_pulse_vpac_out_{i}_en_spare_pend_0_pulse_clr — Enable Clear for pulse_vpac_out_{i}_en_spare_pend_0_pulse
  [15] enable_pulse_vpac_out_{i}_en_spare_dec_1_clr — Enable Clear for pulse_vpac_out_{i}_en_spare_dec_1
  [14] enable_pulse_vpac_out_{i}_en_spare_dec_0_clr — Enable Clear for pulse_vpac_out_{i}_en_spare_dec_0
  [13] enable_pulse_vpac_out_{i}_en_tdone_6_clr — Enable Clear for pulse_vpac_out_{i}_en_tdone_6
  [12] enable_pulse_vpac_out_{i}_en_tdone_5_clr — Enable Clear for pulse_vpac_out_{i}_en_tdone_5
  [11] enable_pulse_vpac_out_{i}_en_tdone_4_clr — Enable Clear for pulse_vpac_out_{i}_en_tdone_4
  [9] enable_pulse_vpac_out_{i}_en_tdone_2_clr — Enable Clear for pulse_vpac_out_{i}_en_tdone_2
  [7] enable_pulse_vpac_out_{i}_en_tdone_0_clr — Enable Clear for pulse_vpac_out_{i}_en_tdone_0
  [n] enable_pulse_vpac_out_{i}_en_pipe_done_{n}_clr (n=0..6) — Enable Clear for pulse_vpac_out_{i}_en_pipe_done_{n}
{0x3D0+0x20*i} enable_clr_reg_pulse_vpac_out_{i}_4 (i=0..5) — Enable Clear Register {8i+52}
  [n] enable_pulse_vpac_out_{i}_en_utc0_complete_{n}_clr (n=0..31) — Enable Clear for pulse_vpac_out_{i}_en_utc0_complete_{n}
{0x3D4+0x20*i} enable_clr_reg_pulse_vpac_out_{i}_5 (i=0..5) — Enable Clear Register {8i+53}
  [n] enable_pulse_vpac_out_{i}_en_utc1_complete_{n}_clr (n=0..31) — Enable Clear for pulse_vpac_out_{i}_en_utc1_complete_{n}
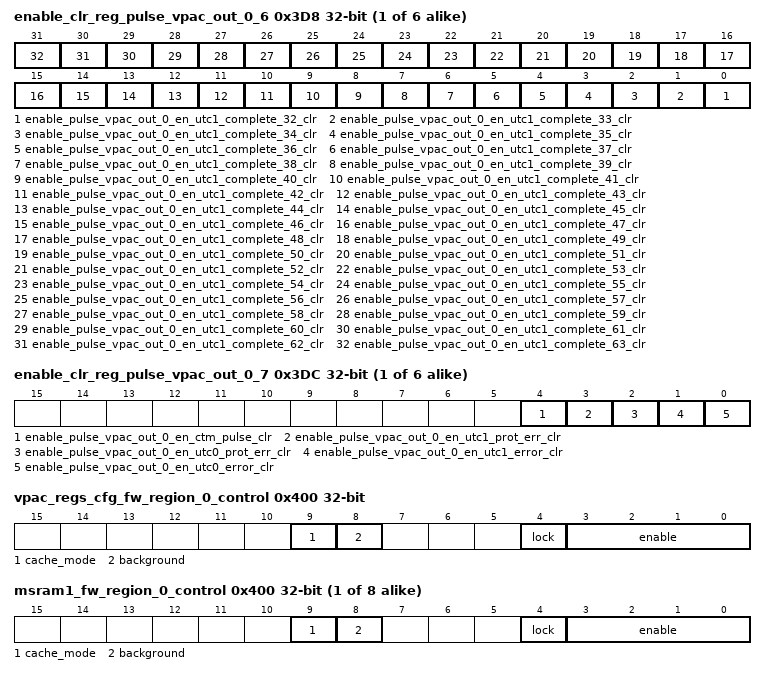
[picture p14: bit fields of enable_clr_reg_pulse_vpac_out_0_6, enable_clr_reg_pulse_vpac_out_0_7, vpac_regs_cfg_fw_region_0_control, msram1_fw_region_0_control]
{0x3D8+0x20*i} enable_clr_reg_pulse_vpac_out_{i}_6 (i=0..5) — Enable Clear Register {8i+54}
  [n-32] enable_pulse_vpac_out_{i}_en_utc1_complete_{n}_clr (n=32..63) — Enable Clear for pulse_vpac_out_{i}_en_utc1_complete_{n}
{0x3DC+0x20*i} enable_clr_reg_pulse_vpac_out_{i}_7 (i=0..5) — Enable Clear Register {8i+55}
  [4] enable_pulse_vpac_out_{i}_en_ctm_pulse_clr — Enable Clear for pulse_vpac_out_{i}_en_ctm_pulse
  [3] enable_pulse_vpac_out_{i}_en_utc1_prot_err_clr — Enable Clear for pulse_vpac_out_{i}_en_utc1_prot_err
  [2] enable_pulse_vpac_out_{i}_en_utc0_prot_err_clr — Enable Clear for pulse_vpac_out_{i}_en_utc0_prot_err
  [1] enable_pulse_vpac_out_{i}_en_utc1_error_clr — Enable Clear for pulse_vpac_out_{i}_en_utc1_error
  [0] enable_pulse_vpac_out_{i}_en_utc0_error_clr — Enable Clear for pulse_vpac_out_{i}_en_utc0_error
0x400 vpac_regs_cfg_fw_region_0_control — The FW Region 0 Control Register defines the control fields for the slave vpac_regs.vpac_regs_cfg region 0 firewall.
  [9] cache_mode — Cache mode for region. Set to 1 to check cache permissions. Set to 0 to ignore cache permissions.
  [8] background — Background enable for region. There can be 1 backgroun region per FW and foreground regions can have overlapping addresses only with the background region.
  [4] lock — Lock region. Once set region values cannot be modified.
  [3:0] enable — Enable region. A value of 0xA enables, others disable.
{0x400+0x20*i} msram1_fw_region_{i}_control (i=0..7) — The FW Region {i} Control Register defines the control fields for the slave ksbus_msram1.slv region {i} firewall.
  fields as vpac_regs_cfg_fw_region_0_control
{0x404+4i} vpac_regs_cfg_fw_region_0_permission_{i} (i=0..2) — The FW Region 0 Permission {i} Register defines the permissions for the slave vpac_regs.vpac_regs_cfg region 0 firewall.
  [23:16] priv_id — Allowed privid.
  [15] nonsec_user_debug — Non-secure user debug allowed.
  [14] nonsec_user_cacheable — Non-secure user cacheable allowed.
  [13] nonsec_user_read — Non-secure user read allowed.
  [12] nonsec_user_write — Non-secure user write allowed.
  [11] nonsec_supv_debug — Non-secure supervisor debug allowed.
  [10] nonsec_supv_cacheable — Non-secure supervisor cacheable allowed.
  [9] nonsec_supv_read — Non-secure supervisor read allowed.
  [8] nonsec_supv_write — Non-secure supervisor write allowed.
  [7] sec_user_debug — Secure user debug allowed.
  [6] sec_user_cacheable — Secure user cacheable allowed.
  [5] sec_user_read — Secure user read allowed.
  [4] sec_user_write — Secure user write allowed.
  [3] sec_supv_debug — Secure supervisor debug allowed.
  [2] sec_supv_cacheable — Secure supervisor cacheable allowed.
  [1] sec_supv_read — Secure supervisor read allowed.
  [0] sec_supv_write — Secure supervisor write allowed.
{0x404+0x20*i} msram1_fw_region_{i}_permission_0 (i=0..7) — The FW Region {i} Permission 0 Register defines the permissions for the slave ksbus_msram1.slv region {i} firewall.
  fields as vpac_regs_cfg_fw_region_0_permission_0
{0x408+0x20*i} msram1_fw_region_{i}_permission_1 (i=0..7) — The FW Region {i} Permission 1 Register defines the permissions for the slave ksbus_msram1.slv region {i} firewall.
  fields as vpac_regs_cfg_fw_region_0_permission_0
{0x40C+0x20*i} msram1_fw_region_{i}_permission_2 (i=0..7) — The FW Region {i} Permission 2 Register defines the permissions for the slave ksbus_msram1.slv region {i} firewall.
  fields as vpac_regs_cfg_fw_region_0_permission_0
0x410 HWA4_prod10_control — Controlling producer socket10 for HWA4
  [27:24] mask_select — define which tdone_mask apply to prod socket 10. tdone_mask[mask_select] applies to prod_socket10
  [8:1] cons_select — consumer select for HWA4 prod socket 10. Used in decrementing count of producer buffer
  [0] prod_en — '1' -> Producer socket 0 enable , '0' Disable
0x410 vpac_regs_cfg_fw_region_0_start_address_l access per field — The FW Region 0 Start Address Low Register defines the start address bits 31 to 0 for the slave vpac_regs.vpac_regs_cfg region 0 firewall.
  [31:12] start_address_l rw — Start address bits 31 to 12. Lowest 12 bits are forced to 0 as address must be 4KB aligned.
  [11:0] start_address_lsb ro — Start address bits 11 to 0 are forced to 0 as address must be 4KB aligned.
{0x410+0x20*i} msram1_fw_region_{i}_start_address_l access per field (i=0..7) — The FW Region {i} Start Address Low Register defines the start address bits 31 to 0 for the slave ksbus_msram1.slv region {i} firewall.
  fields as vpac_regs_cfg_fw_region_0_start_address_l
0x414 vpac_regs_cfg_fw_region_0_start_address_h — The FW Region 0 Start Address High Register defines the start address bits 47 to 32 for the slave vpac_regs.vpac_regs_cfg region 0 firewall.
  [15:0] start_address_h — Start address bits 47 to 32.
{0x414+0x20*i} msram1_fw_region_{i}_start_address_h (i=0..7) — The FW Region {i} Start Address High Register defines the start address bits 47 to 32 for the slave ksbus_msram1.slv region {i} firewall.
  [15:0] start_address_h — Start address bits 47 to 32.
0x418 vpac_regs_cfg_fw_region_0_end_address_l access per field — The FW Region 0 End Address Low Register defines the end address bits 31 to 0 to include for the slave vpac_regs.vpac_regs_cfg region 0 firewall.
  [31:12] end_address_l rw — End address bits 31 to 12 to include in the match. Lowest 12 bits are forced to 1s as address must be 4KB aligned.
  [11:0] end_address_lsb ro — End address bits 11 to 0 are forced to 1s as address must be 4KB aligned minus 1.
{0x418+0x20*i} msram1_fw_region_{i}_end_address_l access per field (i=0..7) — The FW Region {i} End Address Low Register defines the end address bits 31 to 0 to include for the slave ksbus_msram1.slv region {i} firewall.
  fields as vpac_regs_cfg_fw_region_0_end_address_l
0x41C vpac_regs_cfg_fw_region_0_end_address_h — The FW Region 0 End Address High Register defines the end address bits 47 to 32 to include for the slave vpac_regs.vpac_regs_cfg region 0 firewall.
  [15:0] end_address_h — End address bits 47 to 32 to include in the match.
{0x41C+0x20*i} msram1_fw_region_{i}_end_address_h (i=0..7) — The FW Region {i} End Address High Register defines the end address bits 47 to 32 to include for the slave ksbus_msram1.slv region {i} firewall.
  fields as vpac_regs_cfg_fw_region_0_end_address_h
0x424 HWA5_scheduler_control access per field — Scheduler Control Register
  [12] debug_rdy rw — '0' -> HWA5 Scheduler resources must not be read during halted state. '1'-> HWA5 Scheduler resources are readable during halted state
  [10:7] state ro — Current state of HWA5 Scheduler
  [6] pause rw — '1' -> pause/suspend scheduler , '0' -> resume scheduler
  [5] strm_en rw — '1' -> Streaming input enable, '0' No streaming input
  [3:1] pipeline_num rw — Pipeline Number of HWA5 Scheduler
  [0] sch_en rw — scheduler enable; write '1' to enable scheduler
0x428 HWA5_HOP — Scheduler HOP Control Register. Help in detecting eop within scheduler. Once configured, it counts task/channel starts and stops issuing further starts. Specifically useful for Head of pipe dma scheduler .
  [13:1] hop_thread_count — Number of Task count for Head of pipe
  [0] hop — '1' -> Head of Pipe producer Sch , '0' -> No hop
0x42C HWA5_WDTimer access per field — Watchdog timer control register
  [24:8] wdtimer_count ro — Current value of HWA5 Scheduler watchdog timer count
  [2] wdtimer_mode rw — Watchdog timeout count '1' -> 128K , '0' -> 64K
  [1] wdtimer_status ro — HWA5 Scheduler watchdog timer status '1' -> Timer Active '0' -> Timer Inactive (count is stable)
  [0] wdtimer_en rw — '1' -> activate watchdog timer for 64K VPAC/DMPAC cycles between task start and task done '0' -> Disable watchdog timer
0x430 HWA5_BW_limiter — Scheduler BW Control Register. Processing unit level BW control. Use DMA to eliminate peak system BW within processing units line/Block
  [22:8] BW_cycle_count — Average Cycle count between successive Task Start
  [4:1] BW_token_count — Max Token count to create average BW
  [0] BW_limiter_en — '1' -> Enable BW limiter function for HWA5 sch, '0' --> Disable
0x434 HWA5_cons0_control — Controlling consumer socket 0 for HWA5
  [9:1] prod_select — producer select for HWA5 cons socket 0
  [0] cons_en — '1' -> Consumer socket 0 enable , '0' Disable
